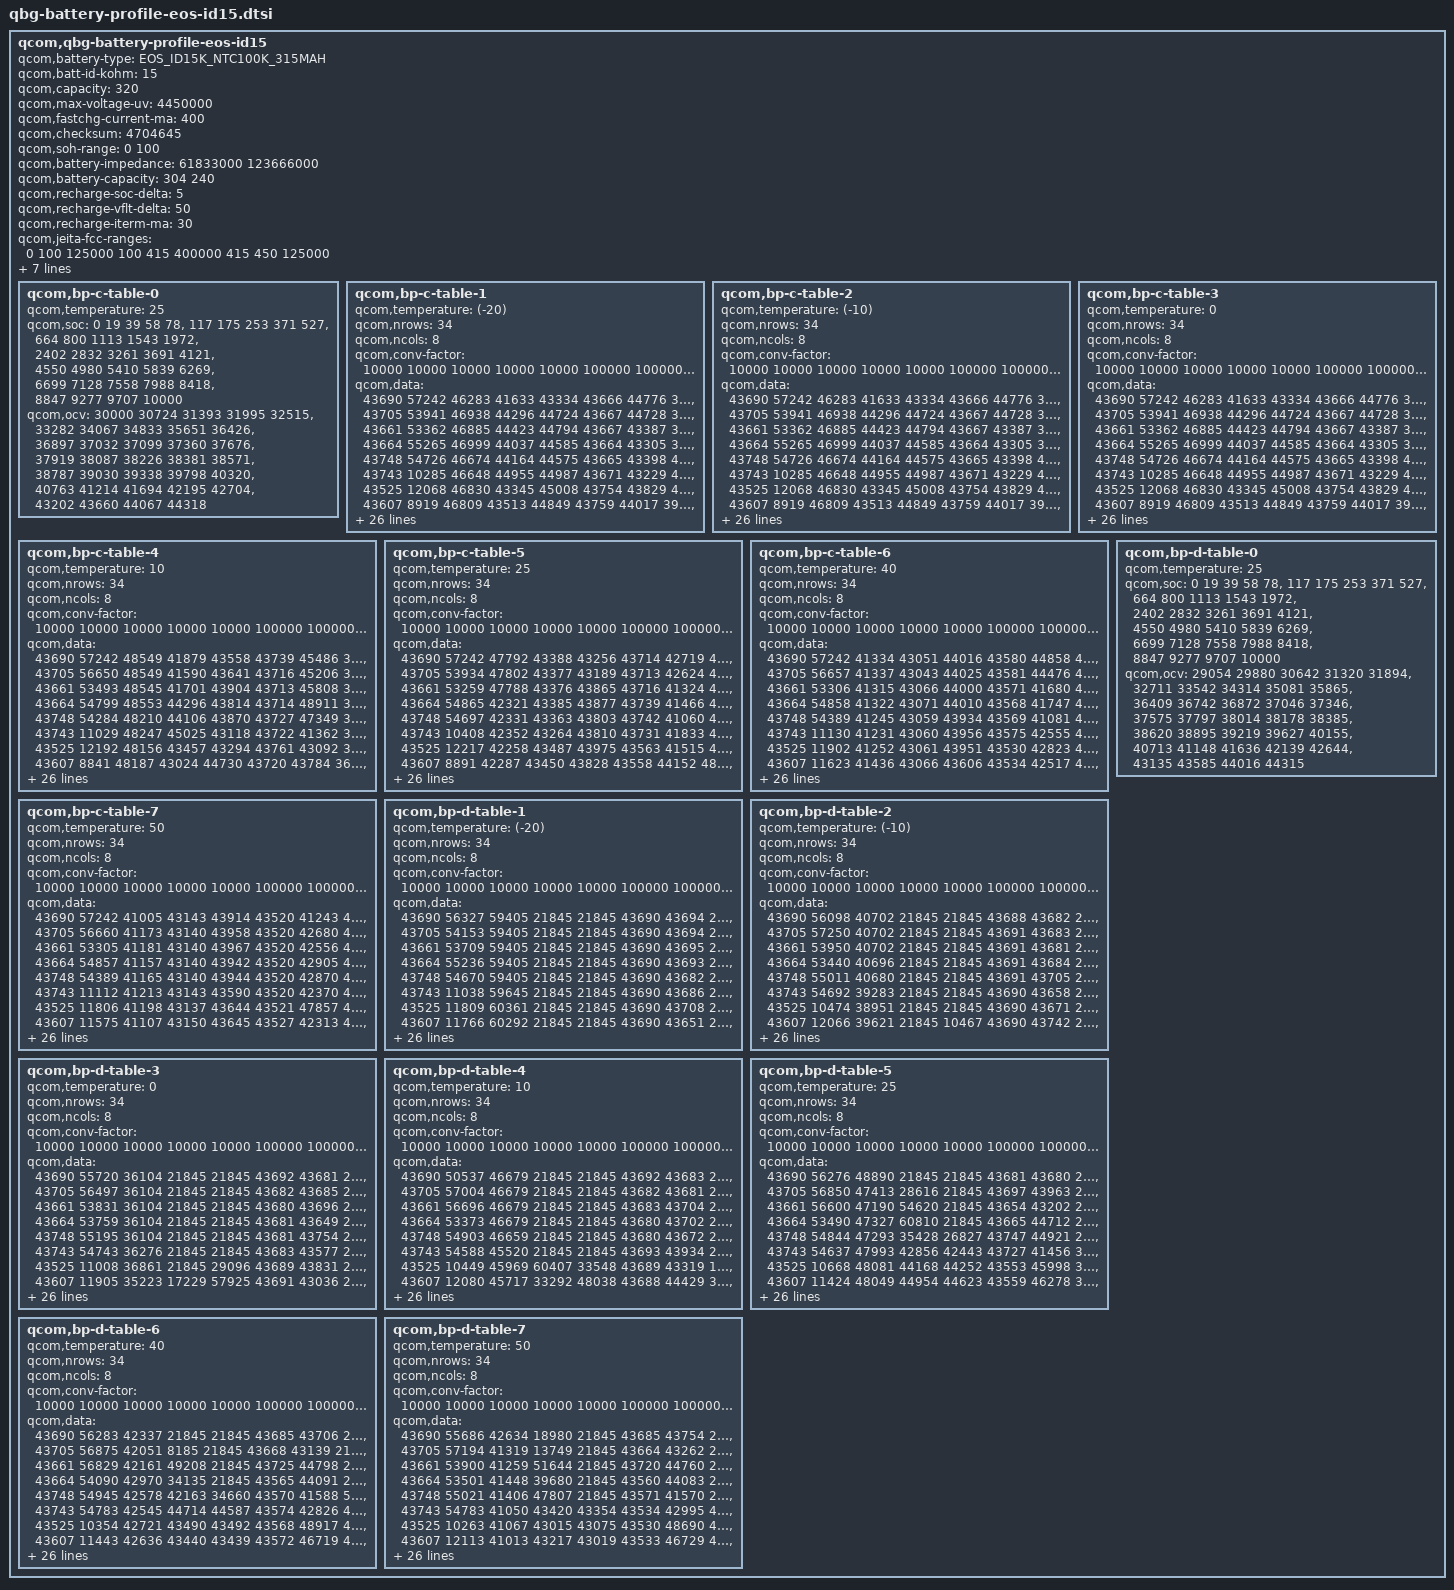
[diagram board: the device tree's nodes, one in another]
// SPDX-License-Identifier: GPL-2.0

/*QBG Profiling Rev. 2.7*/

qcom,qbg-battery-profile-eos-id15 {
	qcom,battery-type = "EOS_ID15K_NTC100K_315MAH";
	qcom,batt-id-kohm = <15>;
	qcom,capacity = <320>;
	qcom,max-voltage-uv = <4450000>;
	qcom,fastchg-current-ma = <400>;
	qcom,checksum = <4704645>; /*@5, 0.005V, 4% */
	qcom,soh-range = <0 100>;
	/*Nominal_Impedance in 10nohm @ SOC 50% 25C* 0:fresh cell, 1: aged cell */
	qcom,battery-impedance = <61833000 123666000>;
	/*Nominal_Capacity in mAh. 0: fresh cell, 1:aged cell*/
	qcom,battery-capacity = <304 240>;
	/*SOC delta (in percent) dropped from EOC SOC to enable recharge*/
	qcom,recharge-soc-delta =<5>;
	/*vfloat delta (in mV) dropped from regular vfloat in recharge*/
	qcom,recharge-vflt-delta =<50>;
	/*termination current (in mA) in recharge*/
	qcom,recharge-iterm-ma = <30>;
	qcom,jeita-fcc-ranges = <0  100 125000
				100 415 400000
				415 450 125000>;

	qcom,jeita-fv-ranges = <0   100 4450000
				100 415 4450000
				415 450 4450000>;

	/* COOL = 10 DegC, WARM = 41 DegC */
	qcom,jeita-soft-thresholds = <0x2b8a 0x14de>;
	/* COLD = 0 DegC, HOT = 45 DegC */
	qcom,jeita-hard-thresholds = <0x3257 0x128c>;
	/* COOL = 12 DegC, WARM = 39 DegC*/
	qcom,jeita-soft-hys-thresholds = <0x2a0b 0x161b>;
	qcom,jeita-soft-fcc-ua = <125000 125000>;
	qcom,jeita-soft-fv-uv = <4450000 4450000>;

	qcom,bp-c-table-0 {
		qcom,temperature = <25>;
		qcom,soc = <    0    19    39    58    78>,
			<  117   175   253   371   527>,
			<  664   800  1113  1543  1972>,
			< 2402  2832  3261  3691  4121>,
			< 4550  4980  5410  5839  6269>,
			< 6699  7128  7558  7988  8418>,
			< 8847  9277  9707 10000>;
		qcom,ocv = <30000 30724 31393 31995 32515>,
			<33282 34067 34833 35651 36426>,
			<36897 37032 37099 37360 37676>,
			<37919 38087 38226 38381 38571>,
			<38787 39030 39338 39798 40320>,
			<40763 41214 41694 42195 42704>,
			<43202 43660 44067 44318>;
	};
	qcom,bp-c-table-1 {
		qcom,temperature = <(-20)>;
		qcom,nrows = <34>;
		qcom,ncols = <8>;
		qcom,conv-factor = <10000 10000 10000 10000 10000 100000 100000 10000>;
		qcom,data = <43690 57242 46283 41633 43334 43666 44776 37732>,
			<43705 53941 46938 44296 44724 43667 44728 37791>,
			<43661 53362 46885 44423 44794 43667 43387 37424>,
			<43664 55265 46999 44037 44585 43664 43305 37546>,
			<43748 54726 46674 44164 44575 43665 43398 40386>,
			<43743 10285 46648 44955 44987 43671 43229 40173>,
			<43525 12068 46830 43345 45008 43754 43829 40573>,
			<43607  8919 46809 43513 44849 43759 44017 39218>,
			<43993  8454 46734 43260 44206 43759 43916 39158>,
			<43173  9242 46730 43852 44198 43745 43958 39916>,
			<43058 15064 45339 43141 44995 43766 43933 39470>,
			<43402 14932 45424 43841 44920 43723 43941 39569>,
			<44787 15309 45363 43014 44956 43726 43985 39579>,
			<44205 14587 45429 41096 43036 43743 42412 40616>,
			<44318 14632 45346 41358 43407 43736 47730 40487>,
			<41928 16086 45506 41321 43465 43738 42439 40657>,
			<41402 16313 45551 42636 43315 43717 42036 40661>,
			<42519 16170 45444 42700 43367 43717 42217 40504>,
			<42177 16219 45479 42510 43348 43716 42836 40450>,
			<47795 15569 45180 42913 44687 43719 42472 40876>,
			<47980 15745 45182 42946 44683 43716 47953 40942>,
			<47582 12935 45123 42754 43385 43719 47996 40842>,
			<49032 13270 45488 42854 43366 43712 42821 40948>,
			<48229 12353 45513 42817 44676 43727 41723 40155>,
			<45783 14027 45415 42113 44627 43723 44178 37622>,
			<45185 14163 46625 41998 45015 43764 44994 36905>,
			<45426 13583 46675 42109 44284 43767 44761 38420>,
			<46892  3017 46952 42422 44344 43767 43372 38157>,
			<46494  2463 46307 42372 41975 43764 43395 59824>,
			<35400  4018 46188 42491 41319 43722 43031 60883>,
			<34853  3502 46531 42264 42395 43720 43228 59176>,
			<36503   582 46430 42245 48689 43726 43144 65332>,
			<36673     0 35553 42396 46912 43727 43841 51441>,
			<36282   335 35790 41740 46970 43520 43917 62932>;
	};
	qcom,bp-c-table-2 {
		qcom,temperature = <(-10)>;
		qcom,nrows = <34>;
		qcom,ncols = <8>;
		qcom,conv-factor = <10000 10000 10000 10000 10000 100000 100000 10000>;
		qcom,data = <43690 57242 46283 41633 43334 43666 44776 37732>,
			<43705 53941 46938 44296 44724 43667 44728 37791>,
			<43661 53362 46885 44423 44794 43667 43387 37424>,
			<43664 55265 46999 44037 44585 43664 43305 37546>,
			<43748 54726 46674 44164 44575 43665 43398 40386>,
			<43743 10285 46648 44955 44987 43671 43229 40173>,
			<43525 12068 46830 43345 45008 43754 43829 40573>,
			<43607  8919 46809 43513 44849 43759 44017 39218>,
			<43993  8454 46734 43260 44206 43759 43916 39158>,
			<43173  9242 46730 43852 44198 43745 43958 39916>,
			<43058 15064 45339 43141 44995 43766 43933 39470>,
			<43402 14932 45424 43841 44920 43723 43941 39569>,
			<44787 15309 45363 43014 44956 43726 43985 39579>,
			<44205 14587 45429 41096 43036 43743 42412 40616>,
			<44318 14632 45346 41358 43407 43736 47730 40487>,
			<41928 16086 45506 41321 43465 43738 42439 40657>,
			<41402 16313 45551 42636 43315 43717 42036 40661>,
			<42519 16170 45444 42700 43367 43717 42217 40504>,
			<42177 16219 45479 42510 43348 43716 42836 40450>,
			<47795 15569 45180 42913 44687 43719 42472 40876>,
			<47980 15745 45182 42946 44683 43716 47953 40942>,
			<47582 12935 45123 42754 43385 43719 47996 40842>,
			<49032 13270 45488 42854 43366 43712 42821 40948>,
			<48229 12353 45513 42817 44676 43727 41723 40155>,
			<45783 14027 45415 42113 44627 43723 44178 37622>,
			<45185 14163 46625 41998 45015 43764 44994 36905>,
			<45426 13583 46675 42109 44284 43767 44761 38420>,
			<46892  3017 46952 42422 44344 43767 43372 38157>,
			<46494  2463 46307 42372 41975 43764 43395 59824>,
			<35400  4018 46188 42491 41319 43722 43031 60883>,
			<34853  3502 46531 42264 42395 43720 43228 59176>,
			<36503   582 46430 42245 48689 43726 43144 65332>,
			<36673     0 35553 42396 46912 43727 43841 51441>,
			<36282   335 35790 41740 46970 43520 43917 62932>;
	};
	qcom,bp-c-table-3 {
		qcom,temperature = <0>;
		qcom,nrows = <34>;
		qcom,ncols = <8>;
		qcom,conv-factor = <10000 10000 10000 10000 10000 100000 100000 10000>;
		qcom,data = <43690 57242 46283 41633 43334 43666 44776 37732>,
			<43705 53941 46938 44296 44724 43667 44728 37791>,
			<43661 53362 46885 44423 44794 43667 43387 37424>,
			<43664 55265 46999 44037 44585 43664 43305 37546>,
			<43748 54726 46674 44164 44575 43665 43398 40386>,
			<43743 10285 46648 44955 44987 43671 43229 40173>,
			<43525 12068 46830 43345 45008 43754 43829 40573>,
			<43607  8919 46809 43513 44849 43759 44017 39218>,
			<43993  8454 46734 43260 44206 43759 43916 39158>,
			<43173  9242 46730 43852 44198 43745 43958 39916>,
			<43058 15064 45339 43141 44995 43766 43933 39470>,
			<43402 14932 45424 43841 44920 43723 43941 39569>,
			<44787 15309 45363 43014 44956 43726 43985 39579>,
			<44205 14587 45429 41096 43036 43743 42412 40616>,
			<44318 14632 45346 41358 43407 43736 47730 40487>,
			<41928 16086 45506 41321 43465 43738 42439 40657>,
			<41402 16313 45551 42636 43315 43717 42036 40661>,
			<42519 16170 45444 42700 43367 43717 42217 40504>,
			<42177 16219 45479 42510 43348 43716 42836 40450>,
			<47795 15569 45180 42913 44687 43719 42472 40876>,
			<47980 15745 45182 42946 44683 43716 47953 40942>,
			<47582 12935 45123 42754 43385 43719 47996 40842>,
			<49032 13270 45488 42854 43366 43712 42821 40948>,
			<48229 12353 45513 42817 44676 43727 41723 40155>,
			<45783 14027 45415 42113 44627 43723 44178 37622>,
			<45185 14163 46625 41998 45015 43764 44994 36905>,
			<45426 13583 46675 42109 44284 43767 44761 38420>,
			<46892  3017 46952 42422 44344 43767 43372 38157>,
			<46494  2463 46307 42372 41975 43764 43395 59824>,
			<35400  4018 46188 42491 41319 43722 43031 60883>,
			<34853  3502 46531 42264 42395 43720 43228 59176>,
			<36503   582 46430 42245 48689 43726 43144 65332>,
			<36673     0 35553 42396 46912 43727 43841 51441>,
			<36282   335 35790 41740 46970 43520 43917 62932>;
	};
	qcom,bp-c-table-4 {
		qcom,temperature = <10>;
		qcom,nrows = <34>;
		qcom,ncols = <8>;
		qcom,conv-factor = <10000 10000 10000 10000 10000 100000 100000 10000>;
		qcom,data = <43690 57242 48549 41879 43558 43739 45486 33000>,
			<43705 56650 48549 41590 43641 43716 45206 33562>,
			<43661 53493 48545 41701 43904 43713 45808 33724>,
			<43664 54799 48553 44296 43814 43714 48911 33500>,
			<43748 54284 48210 44106 43870 43727 47349 36220>,
			<43743 11029 48247 45025 43118 43722 41362 35848>,
			<43525 12192 48156 43457 43294 43761 43092 36762>,
			<43607  8841 48187 43024 44730 43720 43784 36503>,
			<43993  8642 48172 43068 43335 43718 43800 35267>,
			<43173  9431 48260 43109 43475 43730 43136 34841>,
			<43058 15103 48282 43009 43506 43562 43189 34995>,
			<43402 14962 48305 43019 43460 43563 43858 35704>,
			<44787 15235 48317 44592 43861 43552 41545 34944>,
			<44205 14517 49005 44341 43115 43735 42473 36793>,
			<44318 14833 48911 41645 43405 43734 42410 36756>,
			<41928 16116 49131 41665 43393 43728 42465 36771>,
			<41402 15967 48722 41483 43397 43731 42064 36479>,
			<42519 16327 48753 41500 43496 43731 42851 36357>,
			<42177 16199 48743 41489 43485 43730 41343 36376>,
			<47795 15394 48666 41583 43361 43741 41024 36428>,
			<47980 15773 48672 41900 44730 43740 42559 36840>,
			<47582 12961 48681 41935 44703 43741 47907 36657>,
			<49032 13191 48678 41849 43382 43728 46804 36823>,
			<48229 12699 48854 41537 43431 43740 42582 35134>,
			<45783 14251 48864 41500 43426 43736 44334 35310>,
			<45185 13324 48796 41550 43397 43717 44039 35121>,
			<45426  2804 48888 41939 43486 43713 44889 36353>,
			<46892  2179 48666 41137 44776 43714 44624 35867>,
			<46494  3751 49134 40994 44946 43714 44792 33377>,
			<35400  3243 48901 41048 44033 43715 43367 33081>,
			<34853  3410 48367 41393 41917 43719 43409 34253>,
			<36503   892 48162 41080 42976 43736 43012 40886>,
			<36673   469 48243 41923 48701 43558 43175 38444>,
			<36282  1562 48207 43345 47227 44002 43596 40219>;
	};
	qcom,bp-c-table-5 {
		qcom,temperature = <25>;
		qcom,nrows = <34>;
		qcom,ncols = <8>;
		qcom,conv-factor = <10000 10000 10000 10000 10000 100000 100000 10000>;
		qcom,data = <43690 57242 47792 43388 43256 43714 42719 46036>,
			<43705 53934 47802 43377 43189 43713 42624 45980>,
			<43661 53259 47788 43376 43865 43716 41324 45638>,
			<43664 54865 42321 43385 43877 43739 41466 45578>,
			<43748 54697 42331 43363 43803 43742 41060 45823>,
			<43743 10408 42352 43264 43810 43731 41833 48493>,
			<43525 12217 42258 43487 43975 43563 41515 48561>,
			<43607  8891 42287 43450 43828 43558 44152 48176>,
			<43993  8681 42482 43403 43984 43576 44481 48287>,
			<43173  9440 42396 43091 43809 43568 44120 49016>,
			<43058 14987 42378 43097 44012 43574 41731 49137>,
			<43402 14850 42403 43076 43921 43581 41584 49050>,
			<44787 14913 42064 43507 43835 43570 41396 49022>,
			<44205 15194 42008 44586 43008 43556 41553 48412>,
			<44318 14726 42044 44654 43075 43578 41738 48478>,
			<41928 16053 42182 44982 43127 43556 42529 45739>,
			<41402 15981 42219 44980 43065 43556 42911 48431>,
			<42519 16376 42173 44945 43216 43559 42550 48633>,
			<42177 16199 42841 44932 43022 43559 41764 48638>,
			<47795 15361 42869 44655 43509 43558 44913 48595>,
			<47980 15657 42849 44577 44708 43554 44943 48485>,
			<47582 13020 42758 44659 44676 43560 44511 45705>,
			<49032 13056 42805 45003 43386 43564 42719 45807>,
			<48229 12764 42804 44823 43044 43553 47397 48627>,
			<45783 14122 42815 44645 43203 43561 44886 48285>,
			<45185 13713 42791 44615 43204 43563 45053 48381>,
			<45426  2644 42810 44983 43056 43732 44622 48149>,
			<46892  2164 42813 45045 43128 43734 44603 48609>,
			<46494  3705 42753 44192 43396 43731 44588 45767>,
			<35400  3194 42868 44050 44716 43730 44748 45256>,
			<34853   616 42117 44151 44810 43732 43272 46636>,
			<36503    38 42195 44135 41627 43565 43406 46379>,
			<36673  1673 42082 44865 42515 43559 43227 35094>,
			<36282  1972 42008 44784 42700 43729 43860 34994>;
	};
	qcom,bp-c-table-6 {
		qcom,temperature = <40>;
		qcom,nrows = <34>;
		qcom,ncols = <8>;
		qcom,conv-factor = <10000 10000 10000 10000 10000 100000 100000 10000>;
		qcom,data = <43690 57242 41334 43051 44016 43580 44858 48055>,
			<43705 56657 41337 43043 44025 43581 44476 48046>,
			<43661 53306 41315 43066 44000 43571 41680 47681>,
			<43664 54858 41322 43071 44010 43568 41747 47737>,
			<43748 54389 41245 43059 43934 43569 41081 47633>,
			<43743 11130 41231 43060 43956 43575 42555 47653>,
			<43525 11902 41252 43061 43951 43530 42823 47870>,
			<43607 11623 41436 43066 43606 43534 42517 47807>,
			<43993  8619 41460 43224 43605 43521 41439 42365>,
			<43173  9388 41440 43257 43936 43550 41133 42248>,
			<43058  9547 41450 43853 43908 43631 44385 42478>,
			<43402 15046 41375 43843 43584 43543 41333 42076>,
			<44787 14850 41358 43164 43810 43539 41720 42354>,
			<44205 15117 41387 43058 43201 43521 45018 48035>,
			<44318 14408 41050 43122 43208 43521 44454 48007>,
			<41928 14704 41032 43119 43048 43532 44542 48000>,
			<41402 15923 41082 43128 43170 43528 41559 47617>,
			<42519 16273 40983 43076 43894 43575 41588 47666>,
			<42177 16201 40962 43499 43867 43569 44366 47694>,
			<47795 15366 41010 43082 43119 43534 44600 48127>,
			<47980 15673 41005 43204 43371 43532 43300 47895>,
			<47582 12849 41181 43225 43332 43572 44766 47949>,
			<49032 13126 41153 43098 43466 43569 41953 47974>,
			<48229 12571 41166 43516 43173 43529 47759 47730>,
			<45783 14096 41161 43105 43831 43571 44177 42355>,
			<45185 13786 41161 43085 43793 43580 44859 47795>,
			<45426  3051 41166 43431 43182 43579 44575 47673>,
			<46892  2437 41165 43492 43259 43558 44772 48030>,
			<46494  3974 41157 43295 43042 43565 44586 47951>,
			<35400  3460 41002 44772 43425 43554 44786 47543>,
			<34853   944 41015 44555 44709 43557 44714 48649>,
			<36503   124 40981 44598 44874 43573 43266 48351>,
			<36673  1742 41039 43409 44639 43569 43329 48885>,
			<36282  2037 40967 43064 44113 43572 43262 49114>;
	};
	qcom,bp-c-table-7 {
		qcom,temperature = <50>;
		qcom,nrows = <34>;
		qcom,ncols = <8>;
		qcom,conv-factor = <10000 10000 10000 10000 10000 100000 100000 10000>;
		qcom,data = <43690 57242 41005 43143 43914 43520 41243 42053>,
			<43705 56660 41173 43140 43958 43520 42680 42102>,
			<43661 53305 41181 43140 43967 43520 42556 42093>,
			<43664 54857 41157 43140 43942 43520 42905 42011>,
			<43748 54389 41165 43140 43944 43520 42870 42033>,
			<43743 11112 41213 43143 43590 43520 42370 42203>,
			<43525 11806 41198 43137 43644 43521 47857 42218>,
			<43607 11575 41107 43150 43645 43527 42313 42125>,
			<43993  8302 41097 43188 43623 43544 47764 42845>,
			<43173 10005 41144 43174 43629 43542 42486 42857>,
			<43058  9533 41121 43802 43598 43632 40981 42944>,
			<43402 15000 41135 43977 43642 43639 41034 42920>,
			<44787 15045 41809 43788 43819 43643 44887 42838>,
			<44205 15298 41805 43863 43146 43628 44564 42050>,
			<44318 14348 41841 43162 43168 43629 44279 42064>,
			<41928 14601 41848 43177 43159 43629 44884 42076>,
			<41402 16089 41836 43174 43883 43541 41658 42194>,
			<42519 16268 41747 43189 43815 43551 41703 42224>,
			<42177 16242 41731 43205 43788 43521 44494 42008>,
			<47795 15375 41779 43203 43142 43551 44613 42389>,
			<47980 15678 41766 43895 43495 43625 43494 42242>,
			<47582 12803 41768 43830 43270 43540 43311 42344>,
			<49032 12461 41937 43860 43445 43547 44339 42299>,
			<48229 12665 41951 43236 43892 43544 41239 42046>,
			<45783 14178 41945 43855 43990 43550 44945 42855>,
			<45185 13610 41944 43863 43829 43527 44606 42170>,
			<45426  3068 41946 43141 43893 43532 44725 42022>,
			<46892  2537 41947 43018 43176 43575 44551 42375>,
			<46494  4078 41949 43108 43260 43571 44701 42344>,
			<35400  3566 41940 43516 43027 43579 44798 47635>,
			<34853   898 41766 43319 43469 43583 44776 47998>,
			<36503   117 41783 43313 44656 43523 43352 47506>,
			<36673  1732 41755 43216 43366 43523 44720 47703>,
			<36282  1984 41946 43163 44046 43525 43044 47596>;
	};
	qcom,bp-d-table-0 {
		qcom,temperature = <25>;
		qcom,soc = <    0    19    39    58    78>,
			<  117   175   253   371   527>,
			<  664   800  1113  1543  1972>,
			< 2402  2832  3261  3691  4121>,
			< 4550  4980  5410  5839  6269>,
			< 6699  7128  7558  7988  8418>,
			< 8847  9277  9707 10000>;
		qcom,ocv = <29054 29880 30642 31320 31894>,
			<32711 33542 34314 35081 35865>,
			<36409 36742 36872 37046 37346>,
			<37575 37797 38014 38178 38385>,
			<38620 38895 39219 39627 40155>,
			<40713 41148 41636 42139 42644>,
			<43135 43585 44016 44315>;
	};
	qcom,bp-d-table-1 {
		qcom,temperature = <(-20)>;
		qcom,nrows = <34>;
		qcom,ncols = <8>;
		qcom,conv-factor = <10000 10000 10000 10000 10000 100000 100000 10000>;
		qcom,data = <43690 56327 59405 21845 21845 43690 43694 21845>,
			<43705 54153 59405 21845 21845 43690 43694 21845>,
			<43661 53709 59405 21845 21845 43690 43695 21845>,
			<43664 55236 59405 21845 21845 43690 43693 21845>,
			<43748 54670 59405 21845 21845 43690 43682 21845>,
			<43743 11038 59645 21845 21845 43690 43686 21845>,
			<43525 11809 60361 21845 21845 43690 43708 21845>,
			<43607 11766 60292 21845 21845 43690 43651 21845>,
			<43993  8340 59429 21845 10178 43690 43763 21845>,
			<43173  9778 59913 21845 60833 43690 43626 21845>,
			<43058 10085 37214 21845 34128 43690 43952 21845>,
			<43402  9269 36896 21845 34884 43690 43991 21845>,
			<44787  9579 39949  1798 45208 43691 43137 21845>,
			<44205 14870 40737 55121 45396 43691 43231 21845>,
			<44318 15315 39033 63197 48174 43688 43131 21845>,
			<41928 14519 39770 60883 47997 43688 43421 22283>,
			<41402 14364 39844 37491 42176 43689 43468 28750>,
			<42519 14846 34139 34082 42555 43689 43472 28660>,
			<42177 14675 33878 33788 42659 43694 43511  4923>,
			<47795 15881 34094 36728 42685 43694 43442  7725>,
			<47980 16380 34234 35219 42657 43694 43433  1284>,
			<47582 15541 34191 35426 41248 43695 43490   331>,
			<49032 15769 39914 35568 41053 43692 44739   802>,
			<48229 12854 39474 46409 41241 43692 44947   521>,
			<45783 12439 34080 46532 42994 43693 44857   532>,
			<45185 14027 34168 46262 42442 43700 44335   401>,
			<45426 13407 39543 46735 47949 43772 41363  6815>,
			<46892  2577 34084 46596 47541 43771 44339  7082>,
			<46494  2170 34287 46432 47113 43768 41672  6441>,
			<35400  3661 34070 35687 47413 43747 44355  7289>,
			<34853  3141 34267 35135 48794 43755 44459  4248>,
			<36503   588 34283 36686 47493 43679 44832  5864>,
			<36673   400 34180 33707 42471 43659 43469  5759>,
			<36282  2025 34182 33225 43007 43704 43884  4382>;
	};
	qcom,bp-d-table-2 {
		qcom,temperature = <(-10)>;
		qcom,nrows = <34>;
		qcom,ncols = <8>;
		qcom,conv-factor = <10000 10000 10000 10000 10000 100000 100000 10000>;
		qcom,data = <43690 56098 40702 21845 21845 43688 43682 21845>,
			<43705 57250 40702 21845 21845 43691 43683 21845>,
			<43661 53950 40702 21845 21845 43691 43681 21845>,
			<43664 53440 40696 21845 21845 43691 43684 21845>,
			<43748 55011 40680 21845 21845 43691 43705 21845>,
			<43743 54692 39283 21845 21845 43690 43658 21845>,
			<43525 10474 38951 21845 21845 43690 43671 21845>,
			<43607 12066 39621 21845 10467 43690 43742 21845>,
			<43993  9113 33917 21845 34591 43690 43588 21845>,
			<43173  9766 34456 25350 49032 43690 43866 21845>,
			<43058  9459 33651 56217 42397 43691 43425 21845>,
			<43402  9703 33525 57519 41286 43691 43346 22477>,
			<44787 15005 36090 32987 41619 43688 44645  7329>,
			<44205 15294 36627 33395 41095 43689 44793   720>,
			<44318 15122 36667 36775 41774 43689 43339 13462>,
			<41928 14585 36839 35766 41539 43694 43269 15450>,
			<41402 14430 36666 46887 41720 43694 43375 15034>,
			<42519 14642 36706 45282 41658 43695 43378  9214>,
			<42177 16017 35982 48608 41632 43692 43283 10729>,
			<47795 15950 36728 48852 41660 43682 43299 54446>,
			<47980 16145 36011 47561 44509 43686 44653 53297>,
			<47582 15447 36724 47285 44383 43672 41682 54076>,
			<49032 13000 36072 47887 41585 43748 41540 54193>,
			<48229 13127 35999 47953 41824 43764 41561 53867>,
			<45783 12653 35999 47549 41339 43722 41498 54258>,
			<45185 14193 35884 48805 42012 43722 44311 53570>,
			<45426 13689 35938 49084 42304 43766 44895 55293>,
			<46892  2885 36042 45746 42491 43766 44455 54356>,
			<46494  2368 36717 45779 47823 43749 44821 10994>,
			<35400  3922 35946 45866 47645 43751 44863 11090>,
			<34853  3419 36089 45203 47728 43747 44953 10523>,
			<36503   874 35984 45114 42279 43752 44559 10506>,
			<36673   274 36093 45109 41035 43679 44731 11139>,
			<36282  2045 36054 45296 41906 43654 43277 55128>;
	};
	qcom,bp-d-table-3 {
		qcom,temperature = <0>;
		qcom,nrows = <34>;
		qcom,ncols = <8>;
		qcom,conv-factor = <10000 10000 10000 10000 10000 100000 100000 10000>;
		qcom,data = <43690 55720 36104 21845 21845 43692 43681 21845>,
			<43705 56497 36104 21845 21845 43682 43685 21845>,
			<43661 53831 36104 21845 21845 43680 43696 21845>,
			<43664 53759 36104 21845 21845 43681 43649 21845>,
			<43748 55195 36104 21845 21845 43681 43754 21845>,
			<43743 54743 36276 21845 21845 43683 43577 21845>,
			<43525 11008 36861 21845 29096 43689 43831 21845>,
			<43607 11905 35223 17229 57925 43691 43036 21845>,
			<43993 11771 35629 56715 48999 43691 43324 21845>,
			<43173  8608 46453 39250 41507 43691 44731 28478>,
			<43058 10047 46176 45426 44273 43689 44936  9987>,
			<43402  9613 46091 48952 44472 43694 44836 53741>,
			<44787 15010 46109 47758 44211 43682 44986 50166>,
			<44205 14945 46226 47771 44077 43686 44602 53158>,
			<44318 15110 46233 42958 44852 43653 44432 63042>,
			<41928 14374 46857 42651 44996 43750 41755 64599>,
			<41402 14742 46952 41258 44631 43726 41003 64407>,
			<42519 14700 46307 41045 44590 43714 41473 59017>,
			<42177 15914 46258 41400 44793 43713 41089 58246>,
			<47795 16173 46268 41459 45050 43717 42532 58047>,
			<47980 15569 46216 41369 44871 43717 41926 60628>,
			<47582 15677 46245 41417 44236 43739 41614 61388>,
			<49032 12913 46318 41224 44154 43739 44127 60945>,
			<48229 12488 46211 42625 44320 43739 44144 61358>,
			<45783 13982 46248 42608 41888 43739 44241 60670>,
			<45185 13465 46241 42774 41815 43739 44855 60792>,
			<45426  2795 46970 42419 41127 43713 44927 58240>,
			<46892  2275 46264 42380 41033 43726 44970 57522>,
			<46494  3808 46974 42439 41055 43723 44587 57767>,
			<35400  3323 46920 42250 41025 43764 44779 57679>,
			<34853   763 46854 42367 40980 43767 44787 58903>,
			<36503   182 46896 42253 41839 43761 44764 58884>,
			<36673   327 46850 42010 44525 43773 44755 57828>,
			<36282  2040 46956 42144 44864 43775 44750 58120>;
	};
	qcom,bp-d-table-4 {
		qcom,temperature = <10>;
		qcom,nrows = <34>;
		qcom,ncols = <8>;
		qcom,conv-factor = <10000 10000 10000 10000 10000 100000 100000 10000>;
		qcom,data = <43690 50537 46679 21845 21845 43692 43683 21845>,
			<43705 57004 46679 21845 21845 43682 43681 21845>,
			<43661 56696 46679 21845 21845 43683 43704 21845>,
			<43664 53373 46679 21845 21845 43680 43702 21845>,
			<43748 54903 46659 21845 21845 43680 43672 21845>,
			<43743 54588 45520 21845 21845 43693 43934 21845>,
			<43525 10449 45969 60407 33548 43689 43319 18776>,
			<43607 12080 45717 33292 48038 43688 44429  3516>,
			<43993  8828 45738 45720 44518 43689 41547 54294>,
			<43173  9865 48566 42202 43375 43695 41537 51772>,
			<43058  9466 48375 41016 43439 43693 41179 64035>,
			<43402  9682 48169 41128 43429 43683 41981 57706>,
			<44787 15015 48380 44400 43140 43711 41093 59590>,
			<44205 14959 49109 41100 43068 43685 41915 61429>,
			<44318 15178 49053 41866 43393 43697 41260 60283>,
			<41928 14353 49052 44357 43514 43757 41340 38905>,
			<41402 14847 49127 44523 43123 43716 42573 40199>,
			<42519 14657 49097 44471 43068 43741 42431 39202>,
			<42177 15984 49129 44483 43130 43732 45845 39773>,
			<47795 16157 49049 44441 43485 43734 47314 39424>,
			<47980 15420 49105 44450 43341 43734 42681 34099>,
			<47582 15618 48937 44445 44770 43566 41850 34226>,
			<49032 12868 48944 44399 44603 43564 41547 34217>,
			<48229 12509 49117 41534 44974 43560 41489 34183>,
			<45783 14074 49149 41769 44897 43732 41475 34164>,
			<45185 13513 49095 40981 44272 43562 41521 39865>,
			<45426  2770 49123 42624 44068 43729 41876 39137>,
			<46892  2241 49066 42497 44443 43715 44433 39315>,
			<46494  3787 49043 42965 44455 43724 44120 40587>,
			<35400  3317 49140 42123 44116 43720 44118 40518>,
			<34853   760 49050 42192 44466 43767 44105 40822>,
			<36503   183 49084 41991 44036 43773 44465 40795>,
			<36673   328 49051 42094 44627 43748 41654 40517>,
			<36282  1920 48935 42012 44672 43756 41473 39319>;
	};
	qcom,bp-d-table-5 {
		qcom,temperature = <25>;
		qcom,nrows = <34>;
		qcom,ncols = <8>;
		qcom,conv-factor = <10000 10000 10000 10000 10000 100000 100000 10000>;
		qcom,data = <43690 56276 48890 21845 21845 43681 43680 21845>,
			<43705 56850 47413 28616 21845 43697 43963 21845>,
			<43661 56600 47190 54620 21845 43654 43202 21845>,
			<43664 53490 47327 60810 21845 43665 44712 21845>,
			<43748 54844 47293 35428 26827 43747 44921 21845>,
			<43743 54637 47993 42856 42443 43727 41456 38436>,
			<43525 10668 48081 44168 44252 43553 45998 33453>,
			<43607 11424 48049 44954 44623 43559 46278 36595>,
			<43993  9123 47642 44572 43445 43557 46505 35810>,
			<43173  9907 47684 44794 43864 43553 45707 46174>,
			<43058  9363 47676 43331 43797 43735 42737 47102>,
			<43402  9516 47828 44720 43847 43580 41204 47007>,
			<44787 15010 47871 43265 44023 43564 42661 45133>,
			<44205 14876 47750 44694 43834 43732 42168 45334>,
			<44318 15176 42363 44789 43193 43580 42164 45070>,
			<41928 14445 42275 44695 43214 43572 42735 45862>,
			<41402 14607 42488 44696 43132 43531 42611 46049>,
			<42519 16084 42418 44768 43500 43523 42154 46029>,
			<42177 16264 42055 44715 43510 43529 41895 45580>,
			<47795 16219 42110 44777 43088 43524 41888 45699>,
			<47980 15478 41990 44764 43018 43521 41858 48408>,
			<47582 15685 42023 44592 43203 43532 41956 48585>,
			<49032 13209 42201 44574 43211 43531 41884 48615>,
			<48229 12385 42235 44637 43071 43575 41840 48447>,
			<45783 13937 42141 44802 43499 43575 42717 45639>,
			<45185 13731 42117 44187 43331 43574 42200 45240>,
			<45426  2582 42117 44924 44731 43553 44316 45917>,
			<46892  2062 42128 44200 43377 43559 44089 45220>,
			<46494  3633 42213 44065 43501 43556 44543 45200>,
			<35400  3134 42186 44143 43122 43553 44362 45214>,
			<34853   725 42205 44058 43115 43565 41634 45184>,
			<36503   235 42040 44234 43014 43564 41698 45909>,
			<36673   346 41991 44924 43040 43552 41497 45861>,
			<36282  1969 42090 45016 43224 43578 41556 46078>;
	};
	qcom,bp-d-table-6 {
		qcom,temperature = <40>;
		qcom,nrows = <34>;
		qcom,ncols = <8>;
		qcom,conv-factor = <10000 10000 10000 10000 10000 100000 100000 10000>;
		qcom,data = <43690 56283 42337 21845 21845 43685 43706 21845>,
			<43705 56875 42051  8185 21845 43668 43139 21845>,
			<43661 56829 42161 49208 21845 43725 44798 21845>,
			<43664 54090 42970 34135 21845 43565 44091 21845>,
			<43748 54945 42578 42163 34660 43570 41588 59057>,
			<43743 54783 42545 44714 44587 43574 42826 48552>,
			<43525 10354 42721 43490 43492 43568 48917 48672>,
			<43607 11443 42636 43440 43439 43572 46719 47461>,
			<43993  9214 42668 43091 43109 43575 35836 47489>,
			<43173  9859 41288 43126 43990 43520 35425 47915>,
			<43058  9347 41321 43023 43949 43523 47844 47630>,
			<43402  9518 41239 43454 43929 43544 42903 48023>,
			<44787  9555 41225 43065 43591 43533 42874 47866>,
			<44205 14885 41253 43055 43909 43522 42548 47813>,
			<44318 15134 41419 43015 43798 43536 41122 47682>,
			<41928 14360 41450 43008 43199 43629 41092 48058>,
			<41402 14604 41346 43017 43016 43646 41764 48095>,
			<42519 15918 41381 43112 43100 43609 41680 47971>,
			<42177 16286 41055 43440 43215 43950 41870 48083>,
			<47795 15528 41078 43420 43170 43587 41090 48049>,
			<47980 15451 41058 43407 43881 43646 41380 47643>,
			<47582 15703 40979 43095 43817 43626 41080 47774>,
			<49032 13200 40964 43084 43818 43551 41386 47801>,
			<48229 12368 40975 43392 43841 43540 42256 47727>,
			<45783 13909 40970 43508 43073 43537 48043 47953>,
			<45185 13424 41013 43407 43311 43572 41630 47307>,
			<45426  2612 40971 43423 43492 43529 44034 47342>,
			<46892  2261 40962 43280 43051 43551 44396 47292>,
			<46494  3777 40965 44722 43883 43526 41976 47983>,
			<35400  3273 40983 44675 44009 43573 42544 48080>,
			<34853   762 41071 43340 43933 43580 42919 48052>,
			<36503   191 41060 43476 43924 43570 42601 47725>,
			<36673   366 41073 43445 44026 43523 42663 47658>,
			<36282  1603 41039 43125 44021 43536 41412 47859>;
	};
	qcom,bp-d-table-7 {
		qcom,temperature = <50>;
		qcom,nrows = <34>;
		qcom,ncols = <8>;
		qcom,conv-factor = <10000 10000 10000 10000 10000 100000 100000 10000>;
		qcom,data = <43690 55686 42634 18980 21845 43685 43754 21845>,
			<43705 57194 41319 13749 21845 43664 43262 21845>,
			<43661 53900 41259 51644 21845 43720 44760 21845>,
			<43664 53501 41448 39680 21845 43560 44083 21845>,
			<43748 55021 41406 47807 21845 43571 41570 21845>,
			<43743 54783 41050 43420 43354 43534 42995 47576>,
			<43525 10263 41067 43015 43075 43530 48690 47909>,
			<43607 12113 41013 43217 43019 43533 46729 47735>,
			<43993  9105 41175 43209 43045 43522 35364 47659>,
			<43173  9888 41161 43260 43994 43525 35716 42368>,
			<43058  9391 41214 43156 43586 43550 49108 42203>,
			<43402  9714 41185 43066 43959 43527 41463 42069>,
			<44787  9586 41105 43165 43539 43547 47875 42121>,
			<44205 15047 41101 43846 43963 43630 42748 42171>,
			<44318 15161 41126 43156 43993 43647 41367 41999>,
			<41928 14373 41821 43184 43898 43645 41760 42007>,
			<41402 14637 41794 43167 43168 43940 41853 42413>,
			<42519 15915 41840 43030 43138 44031 41012 42254>,
			<42177 16383 41830 43091 43187 43959 42928 42338>,
			<47795 15540 41748 43022 43181 43613 41945 42489>,
			<47980 15790 41755 43058 43837 43593 41163 42093>,
			<47582 12965 41740 43055 43907 43620 42769 42134>,
			<49032 13285 41781 43235 43923 43624 42528 42175>,
			<48229 12710 41789 43253 43889 43630 42791 42007>,
			<45783 14253 41784 43218 43133 43630 43006 42364>,
			<45185 13437 41786 43234 43500 43549 44097 47799>,
			<45426  2612 41787 43011 43025 43629 44477 47791>,
			<46892  2268 41784 43502 43882 43646 41773 42268>,
			<46494  3785 41778 43515 44003 43546 41113 42483>,
			<35400  3313 41780 43406 43950 43570 42538 42078>,
			<34853   751 41743 43128 43613 43570 42893 42043>,
			<36503   163 41754 43222 43606 43530 42563 42216>,
			<36673   285 41834 43163 43967 43545 41221 42145>,
			<36282  1648 41830 43182 43917 43540 40981 42832>;
	};
};
